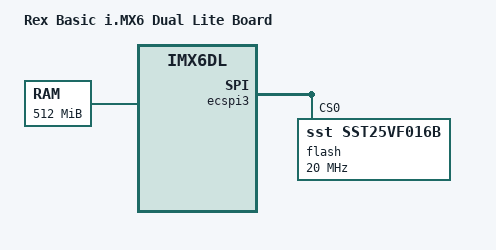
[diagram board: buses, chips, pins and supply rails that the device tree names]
// SPDX-License-Identifier: GPL-2.0-only
/*
 * Copyright 2014 FEDEVEL, Inc.
 *
 * Author: Robert Nelson <robertcnelson@gmail.com>
 */
/dts-v1/;
#include "imx6dl.dtsi"
#include "imx6qdl-rex.dtsi"

/ {
	model = "Rex Basic i.MX6 Dual Lite Board";
	compatible = "rex,imx6dl-rex-basic", "fsl,imx6dl";

	memory@10000000 {
		device_type = "memory";
		reg = <0x10000000 0x20000000>;
	};
};

&ecspi3 {
	flash: flash@0 {
		compatible = "sst,sst25vf016b", "jedec,spi-nor";
		spi-max-frequency = <20000000>;
		reg = <0>;
	};
};
